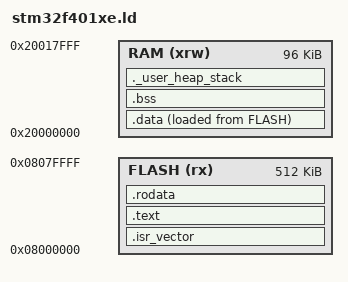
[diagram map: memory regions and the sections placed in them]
/*
 * @file linker_script.ld
 * @brief Linker script for STM32F401RE (Nucleo-F401RE)
 * 
 * Memory Map:
 *   FLASH: 512KB @ 0x08000000
 *   RAM:   96KB  @ 0x20000000
 * 
 * @author Embedded C Architecture Course
 */

ENTRY(Reset_Handler)

/* Specify the memory areas */
MEMORY
{
    FLASH (rx)      : ORIGIN = 0x08000000, LENGTH = 512K
    RAM (xrw)       : ORIGIN = 0x20000000, LENGTH = 96K
}

/* Define output sections */
SECTIONS
{
    /* The startup code goes first into FLASH */
    .isr_vector :
    {
        . = ALIGN(4);
        KEEP(*(.isr_vector)) /* Startup code */
        . = ALIGN(4);
    } > FLASH

    /* The program code and other data goes into FLASH */
    .text :
    {
        . = ALIGN(4);
        *(.text)           /* .text sections (code) */
        *(.text*)          /* .text* sections (code) */
        *(.glue_7)         /* glue arm to thumb code */
        *(.glue_7t)        /* glue thumb to arm code */
        *(.eh_frame)

        KEEP (*(.init))
        KEEP (*(.fini))

        . = ALIGN(4);
        _etext = .;        /* define a global symbols at end of code */
    } > FLASH

    /* Constant data goes into FLASH */
    .rodata :
    {
        . = ALIGN(4);
        *(.rodata)         /* .rodata sections (constants, strings, etc.) */
        *(.rodata*)        /* .rodata* sections (constants, strings, etc.) */
        . = ALIGN(4);
    } > FLASH

    /* Used by the startup to initialize data */
    _sidata = LOADADDR(.data);

    /* Initialized data sections goes into RAM, load LMA copy from FLASH */
    .data : 
    {
        . = ALIGN(4);
        _sdata = .;        /* create a global symbol at data start */
        *(.data)           /* .data sections */
        *(.data*)          /* .data* sections */

        . = ALIGN(4);
        _edata = .;        /* define a global symbol at data end */
    } > RAM AT > FLASH

    /* Uninitialized data section */
    .bss :
    {
        /* This is used by the startup in order to initialize the .bss secion */
        _sbss = .;         /* define a global symbol at bss start */
        __bss_start__ = _sbss;
        *(.bss)
        *(.bss*)
        *(COMMON)

        . = ALIGN(4);
        _ebss = .;         /* define a global symbol at bss end */
        __bss_end__ = _ebss;
    } > RAM

    /* User_heap_stack section, used to check that there is enough RAM left */
    ._user_heap_stack :
    {
        . = ALIGN(8);
        PROVIDE ( end = . );
        PROVIDE ( _end = . );
        . = . + 0x400; /* Min heap */
        . = . + 0x800; /* Min stack */
        . = ALIGN(8);
    } > RAM

    /* Remove information from the standard libraries */
    /DISCARD/ :
    {
        libc.a ( * )
        libm.a ( * )
        libgcc.a ( * )
    }

    .ARM.attributes 0 : { *(.ARM.attributes) }
}
